AUTOSAR XML (schema 4-2-2)
package /STELLANTIS/EPT/ASWCs
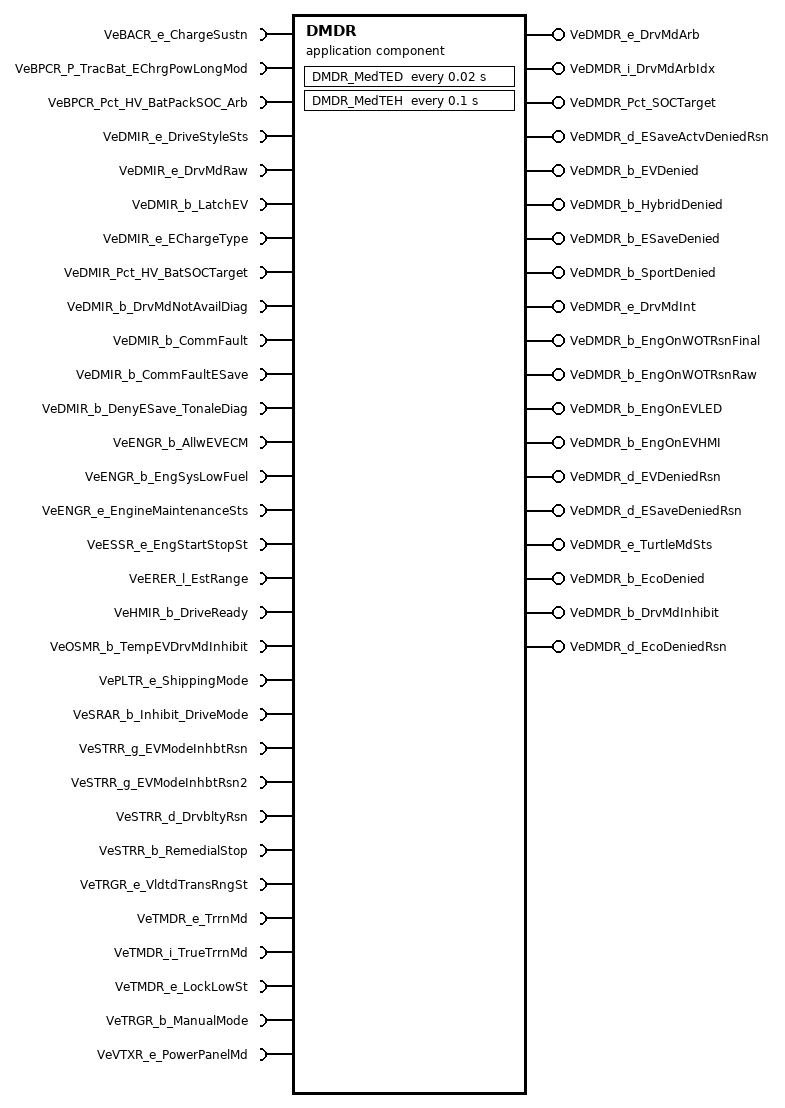
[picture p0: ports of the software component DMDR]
  application sw component type DMDR
    31 x require port:
      VeBACR_e_ChargeSustn: nonqueued-receiver-com-spec{data-element=Value, init-value=CeBACR_e_ChargeSustaining}, required-interface=VeBACR_e_ChargeSustn
      VeBPCR_P_TracBat_EChrgPowLongMod: nonqueued-receiver-com-spec{data-element=Value, init-value=0}, required-interface=VeBPCR_P_TracBat_EChrgPowLongMod
      VeBPCR_Pct_HV_BatPackSOC_Arb: nonqueued-receiver-com-spec{data-element=Value, init-value=0}, required-interface=VeBPCR_Pct_HV_BatPackSOC_Arb
      VeDMIR_e_DriveStyleSts: nonqueued-receiver-com-spec{data-element=Value, init-value=CeDMIR_e_Normal}, required-interface=VeDMIR_e_DriveStyleSts
      VeDMIR_e_DrvMdRaw: nonqueued-receiver-com-spec{data-element=Value, init-value=CeDMDR_e_NoDrvMd}, required-interface=VeDMIR_e_DrvMdRaw
      VeDMIR_b_LatchEV: nonqueued-receiver-com-spec{data-element=Value, init-value=0}, required-interface=VeDMIR_b_LatchEV
      VeDMIR_e_EChargeType: nonqueued-receiver-com-spec{data-element=Value, init-value=CeDMDR_e_Passive_Charging}, required-interface=VeDMIR_e_EChargeType
      VeDMIR_Pct_HV_BatSOCTarget: nonqueued-receiver-com-spec{data-element=Value, init-value=0}, required-interface=VeDMIR_Pct_HV_BatSOCTarget
      VeDMIR_b_DrvMdNotAvailDiag: nonqueued-receiver-com-spec{data-element=Value, init-value=0}, required-interface=VeDMIR_b_DrvMdNotAvailDiag
      VeDMIR_b_CommFault: nonqueued-receiver-com-spec{data-element=Value, init-value=0}, required-interface=VeDMIR_b_CommFault
      VeDMIR_b_CommFaultESave: nonqueued-receiver-com-spec{data-element=Value, init-value=0}, required-interface=VeDMIR_b_CommFaultESave
      VeDMIR_b_DenyESave_TonaleDiag: nonqueued-receiver-com-spec{data-element=Value, init-value=0}, required-interface=VeDMIR_b_DenyESave_TonaleDiag
      VeENGR_b_AllwEVECM: nonqueued-receiver-com-spec{data-element=Value, init-value=0}, required-interface=VeENGR_b_AllwEVECM
      VeENGR_b_EngSysLowFuel: nonqueued-receiver-com-spec{data-element=Value, init-value=0}, required-interface=VeENGR_b_EngSysLowFuel
      VeENGR_e_EngineMaintenanceSts: nonqueued-receiver-com-spec{data-element=Value, init-value=CeENGR_e_Inactive}, required-interface=VeENGR_e_EngineMaintenanceSts
      VeESSR_e_EngStartStopSt: nonqueued-receiver-com-spec{data-element=Value, init-value=CeESSR_e_EngOff}, required-interface=VeESSR_e_EngStartStopSt
      VeERER_l_EstRange: nonqueued-receiver-com-spec{data-element=Value, init-value=0}, required-interface=VeERER_l_EstRange
      VeHMIR_b_DriveReady: nonqueued-receiver-com-spec{data-element=Value, init-value=0}, required-interface=VeHMIR_b_DriveReady
      VeOSMR_b_TempEVDrvMdInhibit: nonqueued-receiver-com-spec{data-element=Value, init-value=0}, required-interface=VeOSMR_b_TempEVDrvMdInhibit
      VePLTR_e_ShippingMode: nonqueued-receiver-com-spec{data-element=Value, init-value=CePLTR_e_ShipingMode_CUST_MD}, required-interface=VePLTR_e_ShippingMode
      VeSRAR_b_Inhibit_DriveMode: nonqueued-receiver-com-spec{data-element=Value, init-value=0}, required-interface=VeSRAR_b_Inhibit_DriveMode
      VeSTRR_g_EVModeInhbtRsn: nonqueued-receiver-com-spec{data-element=Value, init-value=0}, required-interface=VeSTRR_g_EVModeInhbtRsn
      VeSTRR_g_EVModeInhbtRsn2: nonqueued-receiver-com-spec{data-element=Value, init-value=0}, required-interface=VeSTRR_g_EVModeInhbtRsn2
      VeSTRR_d_DrvbltyRsn: nonqueued-receiver-com-spec{data-element=Value, init-value=0}, required-interface=VeSTRR_d_DrvbltyRsn
      VeSTRR_b_RemedialStop: nonqueued-receiver-com-spec{data-element=Value, init-value=0}, required-interface=VeSTRR_b_RemedialStop
      VeTRGR_e_VldtdTransRngSt: nonqueued-receiver-com-spec{data-element=Value, init-value=CeTRGR_e_NoSelectionAvailable}, required-interface=VeTRGR_e_VldtdTransRngSt
      VeTMDR_e_TrrnMd: nonqueued-receiver-com-spec{data-element=Value, init-value=CeTMDR_e_NotDefine}, required-interface=VeTMDR_e_TrrnMd
      VeTMDR_i_TrueTrrnMd: nonqueued-receiver-com-spec{data-element=Value, init-value=0}, required-interface=VeTMDR_i_TrueTrrnMd
      VeTMDR_e_LockLowSt: nonqueued-receiver-com-spec{data-element=Value, init-value=CeTMDR_e_Off}, required-interface=VeTMDR_e_LockLowSt
      VeTRGR_b_ManualMode: nonqueued-receiver-com-spec{data-element=Value, init-value=0}, required-interface=VeTRGR_b_ManualMode
      VeVTXR_e_PowerPanelMd: nonqueued-receiver-com-spec{data-element=Value, init-value=CeVTXR_e_DefaultMd}, required-interface=VeVTXR_e_PowerPanelMd
    19 x provide port:
      VeDMDR_e_DrvMdArb: variation-point={short-label=vpVeDMDR_e_DrvMdArb, sw-syscond=1}, nonqueued-sender-com-spec{data-element=Value, init-value=CeDMDR_e_NoDrvMd}, provided-interface=VeDMDR_e_DrvMdArb
      VeDMDR_i_DrvMdArbIdx: variation-point={short-label=vpVeDMDR_i_DrvMdArbIdx, sw-syscond=1}, nonqueued-sender-com-spec{data-element=Value, init-value=0}, provided-interface=VeDMDR_i_DrvMdArbIdx
      VeDMDR_Pct_SOCTarget: variation-point={short-label=vpVeDMDR_Pct_SOCTarget, sw-syscond=1}, nonqueued-sender-com-spec{data-element=Value, init-value=0}, provided-interface=VeDMDR_Pct_SOCTarget
      VeDMDR_d_ESaveActvDeniedRsn: variation-point={short-label=vpVeDMDR_d_ESaveActvDeniedRsn, sw-syscond=1}, nonqueued-sender-com-spec{data-element=Value, init-value=0}, provided-interface=VeDMDR_d_ESaveActvDeniedRsn
      VeDMDR_b_EVDenied: variation-point={short-label=vpVeDMDR_b_EVDenied, sw-syscond=1}, nonqueued-sender-com-spec{data-element=Value, init-value=0}, provided-interface=VeDMDR_b_EVDenied
      VeDMDR_b_HybridDenied: variation-point={short-label=vpVeDMDR_b_HybridDenied, sw-syscond=1}, nonqueued-sender-com-spec{data-element=Value, init-value=0}, provided-interface=VeDMDR_b_HybridDenied
      VeDMDR_b_ESaveDenied: variation-point={short-label=vpVeDMDR_b_ESaveDenied, sw-syscond=1}, nonqueued-sender-com-spec{data-element=Value, init-value=0}, provided-interface=VeDMDR_b_ESaveDenied
      VeDMDR_b_SportDenied: variation-point={short-label=vpVeDMDR_b_SportDenied, sw-syscond=1}, nonqueued-sender-com-spec{data-element=Value, init-value=0}, provided-interface=VeDMDR_b_SportDenied
      VeDMDR_e_DrvMdInt: variation-point={short-label=vpVeDMDR_e_DrvMdInt, sw-syscond=1}, nonqueued-sender-com-spec{data-element=Value, init-value=CeDMDR_e_NoDrvMd}, provided-interface=VeDMDR_e_DrvMdInt
      VeDMDR_b_EngOnWOTRsnFinal: variation-point={short-label=vpVeDMDR_b_EngOnWOTRsnFinal, sw-syscond=1}, nonqueued-sender-com-spec{data-element=Value, init-value=0}, provided-interface=VeDMDR_b_EngOnWOTRsnFinal
      VeDMDR_b_EngOnWOTRsnRaw: variation-point={short-label=vpVeDMDR_b_EngOnWOTRsnRaw, sw-syscond=1}, nonqueued-sender-com-spec{data-element=Value, init-value=0}, provided-interface=VeDMDR_b_EngOnWOTRsnRaw
      VeDMDR_b_EngOnEVLED: variation-point={short-label=vpVeDMDR_b_EngOnEVLED, sw-syscond=1}, nonqueued-sender-com-spec{data-element=Value, init-value=0}, provided-interface=VeDMDR_b_EngOnEVLED
      VeDMDR_b_EngOnEVHMI: variation-point={short-label=vpVeDMDR_b_EngOnEVHMI, sw-syscond=1}, nonqueued-sender-com-spec{data-element=Value, init-value=0}, provided-interface=VeDMDR_b_EngOnEVHMI
      VeDMDR_d_EVDeniedRsn: variation-point={short-label=vpVeDMDR_d_EVDeniedRsn, sw-syscond=1}, nonqueued-sender-com-spec{data-element=Value, init-value=0}, provided-interface=VeDMDR_d_EVDeniedRsn
      VeDMDR_d_ESaveDeniedRsn: variation-point={short-label=vpVeDMDR_d_ESaveDeniedRsn, sw-syscond=1}, nonqueued-sender-com-spec{data-element=Value, init-value=0}, provided-interface=VeDMDR_d_ESaveDeniedRsn
      VeDMDR_e_TurtleMdSts: variation-point={short-label=vpVeDMDR_e_TurtleMdSts, sw-syscond=1}, nonqueued-sender-com-spec{data-element=Value, init-value=CeDMDR_e_No_Turtle_Mode}, provided-interface=VeDMDR_e_TurtleMdSts
      VeDMDR_b_EcoDenied: variation-point={short-label=vpVeDMDR_b_EcoDenied, sw-syscond=1}, nonqueued-sender-com-spec{data-element=Value, init-value=0}, provided-interface=VeDMDR_b_EcoDenied
      VeDMDR_b_DrvMdInhibit: nonqueued-sender-com-spec{data-element=Value, init-value=0}, provided-interface=VeDMDR_b_DrvMdInhibit
      VeDMDR_d_EcoDeniedRsn: variation-point={short-label=vpVeDMDR_d_EcoDeniedRsn, sw-syscond=1}, nonqueued-sender-com-spec{data-element=Value, init-value=0}, provided-interface=VeDMDR_d_EcoDeniedRsn
    behavior IB_DMDR: data-type-mapping=msADTtoIDTMapping, handle-termination-and-restart=NO-SUPPORT
      timing event Event_MedTED: start-on-event=DMDR_MedTED, period=0.02
      timing event Event_MedTEH: start-on-event=DMDR_MedTEH, period=0.1
      init event Event_DMDR_ac_Init: start-on-event=DMDR_ac_Init
      init event Event_PwrOn: start-on-event=DMDR_PwrOn
      explicit-inter-runnable-variables:
        5 x data, all with category=VALUE, sw-calibration-access=READ-ONLY:
          VeDMDC_e_DriveStyleSts_write_IRV: type=TeDMIR_e_DriveStyleSts, init-value=CeDMIR_e_Normal
          VeDMDC_e_TerrainMd_write_IRV: type=TeTMDR_e_TrrnMd, init-value=CeTMDR_e_NotDefine
          VeDMDC_i_TerrainMdIdx_write_IRV: type=UInt8, init-value=0
          VeDMDC_b_ShippingMd_write_IRV: type=TePLTR_e_ShipingMode, init-value=CePLTR_e_ShipingMode_CUST_MD
          VeDMDR_b_Inhibit_DriveMode_write_IRV: type=Boolean, init-value=0
      4 x runnable:
        DMDR_ac_Init
          data-send-points:
            access OUT_VeDMDR_e_DrvMdArb_Value: accessed-variable=VeDMDR_e_DrvMdArb.Value, variation-point={short-label=vpOUT_VeDMDR_e_DrvMdArb_Value, sw-syscond=1}
            access OUT_VeDMDR_e_DrvMdInt_Value: accessed-variable=VeDMDR_e_DrvMdInt.Value, variation-point={short-label=vpOUT_VeDMDR_e_DrvMdInt_Value, sw-syscond=1}
            access OUT_VeDMDR_e_TurtleMdSts_Value: accessed-variable=VeDMDR_e_TurtleMdSts.Value, variation-point={short-label=vpOUT_VeDMDR_e_TurtleMdSts_Value, sw-syscond=1}
        DMDR_PwrOn
          data-send-points:
            19 x access:
              OUT_VeDMDR_e_DrvMdArb_Value: accessed-variable=VeDMDR_e_DrvMdArb.Value, variation-point={short-label=vpOUT_VeDMDR_e_DrvMdArb_Value, sw-syscond=1}
              OUT_VeDMDR_i_DrvMdArbIdx_Value: accessed-variable=VeDMDR_i_DrvMdArbIdx.Value, variation-point={short-label=vpOUT_VeDMDR_i_DrvMdArbIdx_Value, sw-syscond=1}
              OUT_VeDMDR_Pct_SOCTarget_Value: accessed-variable=VeDMDR_Pct_SOCTarget.Value, variation-point={short-label=vpOUT_VeDMDR_Pct_SOCTarget_Value, sw-syscond=1}
              OUT_VeDMDR_e_DrvMdInt_Value: accessed-variable=VeDMDR_e_DrvMdInt.Value, variation-point={short-label=vpOUT_VeDMDR_e_DrvMdInt_Value, sw-syscond=1}
              OUT_VeDMDR_b_EngOnWOTRsnFinal_Value: accessed-variable=VeDMDR_b_EngOnWOTRsnFinal.Value, variation-point={short-label=vpOUT_VeDMDR_b_EngOnWOTRsnFinal_Value, sw-syscond=1}
              OUT_VeDMDR_b_EngOnWOTRsnRaw_Value: accessed-variable=VeDMDR_b_EngOnWOTRsnRaw.Value, variation-point={short-label=vpOUT_VeDMDR_b_EngOnWOTRsnRaw_Value, sw-syscond=1}
              OUT_VeDMDR_b_EngOnEVLED_Value: accessed-variable=VeDMDR_b_EngOnEVLED.Value, variation-point={short-label=vpOUT_VeDMDR_b_EngOnEVLED_Value, sw-syscond=1}
              OUT_VeDMDR_b_EngOnEVHMI_Value: accessed-variable=VeDMDR_b_EngOnEVHMI.Value, variation-point={short-label=vpOUT_VeDMDR_b_EngOnEVHMI_Value, sw-syscond=1}
              OUT_VeDMDR_d_EcoDeniedRsn_Value: accessed-variable=VeDMDR_d_EcoDeniedRsn.Value, variation-point={short-label=vpOUT_VeDMDR_d_EcoDeniedRsn_Value, sw-syscond=1}
              OUT_VeDMDR_d_ESaveActvDeniedRsn_Value: accessed-variable=VeDMDR_d_ESaveActvDeniedRsn.Value, variation-point={short-label=vpOUT_VeDMDR_d_ESaveActvDeniedRsn_Value, sw-syscond=1}
              OUT_VeDMDR_d_EVDeniedRsn_Value: accessed-variable=VeDMDR_d_EVDeniedRsn.Value, variation-point={short-label=vpOUT_VeDMDR_d_EVDeniedRsn_Value, sw-syscond=1}
              OUT_VeDMDR_d_ESaveDeniedRsn_Value: accessed-variable=VeDMDR_d_ESaveDeniedRsn.Value, variation-point={short-label=vpOUT_VeDMDR_d_ESaveDeniedRsn_Value, sw-syscond=1}
              OUT_VeDMDR_b_EcoDenied_Value: accessed-variable=VeDMDR_b_EcoDenied.Value, variation-point={short-label=vpOUT_VeDMDR_b_EcoDenied_Value, sw-syscond=1}
              OUT_VeDMDR_b_EVDenied_Value: accessed-variable=VeDMDR_b_EVDenied.Value, variation-point={short-label=vpOUT_VeDMDR_b_EVDenied_Value, sw-syscond=1}
              OUT_VeDMDR_b_HybridDenied_Value: accessed-variable=VeDMDR_b_HybridDenied.Value, variation-point={short-label=vpOUT_VeDMDR_b_HybridDenied_Value, sw-syscond=1}
              OUT_VeDMDR_b_ESaveDenied_Value: accessed-variable=VeDMDR_b_ESaveDenied.Value, variation-point={short-label=vpOUT_VeDMDR_b_ESaveDenied_Value, sw-syscond=1}
              OUT_VeDMDR_b_SportDenied_Value: accessed-variable=VeDMDR_b_SportDenied.Value, variation-point={short-label=vpOUT_VeDMDR_b_SportDenied_Value, sw-syscond=1}
              OUT_VeDMDR_e_TurtleMdSts_Value: accessed-variable=VeDMDR_e_TurtleMdSts.Value, variation-point={short-label=vpOUT_VeDMDR_e_TurtleMdSts_Value, sw-syscond=1}
              OUT_VeDMDR_b_DrvMdInhibit_Value: accessed-variable=VeDMDR_b_DrvMdInhibit.Value
          written-local-variables:
            5 x access:
              WV_VeDMDR_b_Inhibit_DriveMode_write_IRV: accessed-variable=VeDMDR_b_Inhibit_DriveMode_write_IRV
              WV_VeDMDC_e_DriveStyleSts_write_IRV: accessed-variable=VeDMDC_e_DriveStyleSts_write_IRV
              WV_VeDMDC_b_ShippingMd_write_IRV: accessed-variable=VeDMDC_b_ShippingMd_write_IRV
              WV_VeDMDC_e_TerrainMd_write_IRV: accessed-variable=VeDMDC_e_TerrainMd_write_IRV
              WV_VeDMDC_i_TerrainMdIdx_write_IRV: accessed-variable=VeDMDC_i_TerrainMdIdx_write_IRV
        DMDR_MedTED
          data-receive-point-by-arguments:
            31 x access:
              IN_VeBACR_e_ChargeSustn_Value: accessed-variable=VeBACR_e_ChargeSustn.Value
              IN_VeBPCR_P_TracBat_EChrgPowLongMod_Value: accessed-variable=VeBPCR_P_TracBat_EChrgPowLongMod.Value
              IN_VeBPCR_Pct_HV_BatPackSOC_Arb_Value: accessed-variable=VeBPCR_Pct_HV_BatPackSOC_Arb.Value
              IN_VeDMIR_Pct_HV_BatSOCTarget_Value: accessed-variable=VeDMIR_Pct_HV_BatSOCTarget.Value
              IN_VeDMIR_b_CommFault_Value: accessed-variable=VeDMIR_b_CommFault.Value
              IN_VeDMIR_b_CommFaultESave_Value: accessed-variable=VeDMIR_b_CommFaultESave.Value
              IN_VeDMIR_b_DenyESave_TonaleDiag_Value: accessed-variable=VeDMIR_b_DenyESave_TonaleDiag.Value
              IN_VeDMIR_b_DrvMdNotAvailDiag_Value: accessed-variable=VeDMIR_b_DrvMdNotAvailDiag.Value
              IN_VeDMIR_b_LatchEV_Value: accessed-variable=VeDMIR_b_LatchEV.Value
              IN_VeDMIR_e_DriveStyleSts_Value: accessed-variable=VeDMIR_e_DriveStyleSts.Value
              IN_VeDMIR_e_DrvMdRaw_Value: accessed-variable=VeDMIR_e_DrvMdRaw.Value
              IN_VeDMIR_e_EChargeType_Value: accessed-variable=VeDMIR_e_EChargeType.Value
              IN_VeENGR_b_AllwEVECM_Value: accessed-variable=VeENGR_b_AllwEVECM.Value
              IN_VeENGR_b_EngSysLowFuel_Value: accessed-variable=VeENGR_b_EngSysLowFuel.Value
              IN_VeENGR_e_EngineMaintenanceSts_Value: accessed-variable=VeENGR_e_EngineMaintenanceSts.Value
              IN_VeERER_l_EstRange_Value: accessed-variable=VeERER_l_EstRange.Value
              IN_VeESSR_e_EngStartStopSt_Value: accessed-variable=VeESSR_e_EngStartStopSt.Value
              IN_VeHMIR_b_DriveReady_Value: accessed-variable=VeHMIR_b_DriveReady.Value
              IN_VeOSMR_b_TempEVDrvMdInhibit_Value: accessed-variable=VeOSMR_b_TempEVDrvMdInhibit.Value
              IN_VePLTR_e_ShippingMode_Value: accessed-variable=VePLTR_e_ShippingMode.Value
              IN_VeSRAR_b_Inhibit_DriveMode_Value: accessed-variable=VeSRAR_b_Inhibit_DriveMode.Value
              IN_VeSTRR_b_RemedialStop_Value: accessed-variable=VeSTRR_b_RemedialStop.Value
              IN_VeSTRR_d_DrvbltyRsn_Value: accessed-variable=VeSTRR_d_DrvbltyRsn.Value
              IN_VeSTRR_g_EVModeInhbtRsn_Value: accessed-variable=VeSTRR_g_EVModeInhbtRsn.Value
              IN_VeSTRR_g_EVModeInhbtRsn2_Value: accessed-variable=VeSTRR_g_EVModeInhbtRsn2.Value
              IN_VeTMDR_e_LockLowSt_Value: accessed-variable=VeTMDR_e_LockLowSt.Value
              IN_VeTMDR_e_TrrnMd_Value: accessed-variable=VeTMDR_e_TrrnMd.Value
              IN_VeTMDR_i_TrueTrrnMd_Value: accessed-variable=VeTMDR_i_TrueTrrnMd.Value
              IN_VeTRGR_b_ManualMode_Value: accessed-variable=VeTRGR_b_ManualMode.Value
              IN_VeTRGR_e_VldtdTransRngSt_Value: accessed-variable=VeTRGR_e_VldtdTransRngSt.Value
              IN_VeVTXR_e_PowerPanelMd_Value: accessed-variable=VeVTXR_e_PowerPanelMd.Value
          data-send-points:
            19 x access:
              OUT_VeDMDR_b_DrvMdInhibit_Value: accessed-variable=VeDMDR_b_DrvMdInhibit.Value
              OUT_VeDMDR_e_DrvMdArb_Value: accessed-variable=VeDMDR_e_DrvMdArb.Value, variation-point={short-label=vpOUT_VeDMDR_e_DrvMdArb_Value, sw-syscond=1}
              OUT_VeDMDR_i_DrvMdArbIdx_Value: accessed-variable=VeDMDR_i_DrvMdArbIdx.Value, variation-point={short-label=vpOUT_VeDMDR_i_DrvMdArbIdx_Value, sw-syscond=1}
              OUT_VeDMDR_Pct_SOCTarget_Value: accessed-variable=VeDMDR_Pct_SOCTarget.Value, variation-point={short-label=vpOUT_VeDMDR_Pct_SOCTarget_Value, sw-syscond=1}
              OUT_VeDMDR_e_DrvMdInt_Value: accessed-variable=VeDMDR_e_DrvMdInt.Value, variation-point={short-label=vpOUT_VeDMDR_e_DrvMdInt_Value, sw-syscond=1}
              OUT_VeDMDR_b_EngOnWOTRsnFinal_Value: accessed-variable=VeDMDR_b_EngOnWOTRsnFinal.Value, variation-point={short-label=vpOUT_VeDMDR_b_EngOnWOTRsnFinal_Value, sw-syscond=1}
              OUT_VeDMDR_b_EngOnWOTRsnRaw_Value: accessed-variable=VeDMDR_b_EngOnWOTRsnRaw.Value, variation-point={short-label=vpOUT_VeDMDR_b_EngOnWOTRsnRaw_Value, sw-syscond=1}
              OUT_VeDMDR_b_EngOnEVLED_Value: accessed-variable=VeDMDR_b_EngOnEVLED.Value, variation-point={short-label=vpOUT_VeDMDR_b_EngOnEVLED_Value, sw-syscond=1}
              OUT_VeDMDR_b_EngOnEVHMI_Value: accessed-variable=VeDMDR_b_EngOnEVHMI.Value, variation-point={short-label=vpOUT_VeDMDR_b_EngOnEVHMI_Value, sw-syscond=1}
              OUT_VeDMDR_d_ESaveActvDeniedRsn_Value: accessed-variable=VeDMDR_d_ESaveActvDeniedRsn.Value, variation-point={short-label=vpOUT_VeDMDR_d_ESaveActvDeniedRsn_Value, sw-syscond=1}
              OUT_VeDMDR_d_EVDeniedRsn_Value: accessed-variable=VeDMDR_d_EVDeniedRsn.Value, variation-point={short-label=vpOUT_VeDMDR_d_EVDeniedRsn_Value, sw-syscond=1}
              OUT_VeDMDR_d_ESaveDeniedRsn_Value: accessed-variable=VeDMDR_d_ESaveDeniedRsn.Value, variation-point={short-label=vpOUT_VeDMDR_d_ESaveDeniedRsn_Value, sw-syscond=1}
              OUT_VeDMDR_d_EcoDeniedRsn_Value: accessed-variable=VeDMDR_d_EcoDeniedRsn.Value, variation-point={short-label=vpOUT_VeDMDR_d_EcoDeniedRsn_Value, sw-syscond=1}
              OUT_VeDMDR_b_EcoDenied_Value: accessed-variable=VeDMDR_b_EcoDenied.Value, variation-point={short-label=vpOUT_VeDMDR_b_EcoDenied_Value, sw-syscond=1}
              OUT_VeDMDR_b_EVDenied_Value: accessed-variable=VeDMDR_b_EVDenied.Value, variation-point={short-label=vpOUT_VeDMDR_b_EVDenied_Value, sw-syscond=1}
              OUT_VeDMDR_b_HybridDenied_Value: accessed-variable=VeDMDR_b_HybridDenied.Value, variation-point={short-label=vpOUT_VeDMDR_b_HybridDenied_Value, sw-syscond=1}
              OUT_VeDMDR_b_ESaveDenied_Value: accessed-variable=VeDMDR_b_ESaveDenied.Value, variation-point={short-label=vpOUT_VeDMDR_b_ESaveDenied_Value, sw-syscond=1}
              OUT_VeDMDR_b_SportDenied_Value: accessed-variable=VeDMDR_b_SportDenied.Value, variation-point={short-label=vpOUT_VeDMDR_b_SportDenied_Value, sw-syscond=1}
              OUT_VeDMDR_e_TurtleMdSts_Value: accessed-variable=VeDMDR_e_TurtleMdSts.Value, variation-point={short-label=vpOUT_VeDMDR_e_TurtleMdSts_Value, sw-syscond=1}
          written-local-variables:
            5 x access:
              WV_VeDMDC_b_ShippingMd_write_IRV: accessed-variable=VeDMDC_b_ShippingMd_write_IRV
              WV_VeDMDC_e_DriveStyleSts_write_IRV: accessed-variable=VeDMDC_e_DriveStyleSts_write_IRV
              WV_VeDMDC_e_TerrainMd_write_IRV: accessed-variable=VeDMDC_e_TerrainMd_write_IRV
              WV_VeDMDC_i_TerrainMdIdx_write_IRV: accessed-variable=VeDMDC_i_TerrainMdIdx_write_IRV
              WV_VeDMDR_b_Inhibit_DriveMode_write_IRV: accessed-variable=VeDMDR_b_Inhibit_DriveMode_write_IRV
        DMDR_MedTEH: variation-point={short-label=vpDMDR_MedTEH, sw-syscond=1}
          data-send-points:
            4 x access:
              OUT_VeDMDR_e_DrvMdArb_Value: accessed-variable=VeDMDR_e_DrvMdArb.Value, variation-point={short-label=vpOUT_VeDMDR_e_DrvMdArb_Value, sw-syscond=1}
              OUT_VeDMDR_i_DrvMdArbIdx_Value: accessed-variable=VeDMDR_i_DrvMdArbIdx.Value, variation-point={short-label=vpOUT_VeDMDR_i_DrvMdArbIdx_Value, sw-syscond=1}
              OUT_VeDMDR_b_EcoDenied_Value: accessed-variable=VeDMDR_b_EcoDenied.Value, variation-point={short-label=vpOUT_VeDMDR_b_EcoDenied_Value, sw-syscond=1}
              OUT_VeDMDR_d_EcoDeniedRsn_Value: accessed-variable=VeDMDR_d_EcoDeniedRsn.Value, variation-point={short-label=vpOUT_VeDMDR_d_EcoDeniedRsn_Value, sw-syscond=1}
          read-local-variables:
            5 x access:
              RV_VeDMDC_b_ShippingMd_write_IRV: accessed-variable=VeDMDC_b_ShippingMd_write_IRV, variation-point={short-label=vpRV_VeDMDC_b_ShippingMd_write_IRV, sw-syscond=1}
              RV_VeDMDC_e_DriveStyleSts_write_IRV: accessed-variable=VeDMDC_e_DriveStyleSts_write_IRV, variation-point={short-label=vpRV_VeDMDC_e_DriveStyleSts_write_IRV, sw-syscond=1}
              RV_VeDMDC_e_TerrainMd_write_IRV: accessed-variable=VeDMDC_e_TerrainMd_write_IRV, variation-point={short-label=vpRV_VeDMDC_e_TerrainMd_write_IRV, sw-syscond=1}
              RV_VeDMDC_i_TerrainMdIdx_write_IRV: accessed-variable=VeDMDC_i_TerrainMdIdx_write_IRV, variation-point={short-label=vpRV_VeDMDC_i_TerrainMdIdx_write_IRV, sw-syscond=1}
              RV_VeDMDR_b_Inhibit_DriveMode_write_IRV: accessed-variable=VeDMDR_b_Inhibit_DriveMode_write_IRV, variation-point={short-label=vpRV_VeDMDR_b_Inhibit_DriveMode_write_IRV, sw-syscond=1}
      7 x variation point proxy, all with category=CONDITION:
        Variant_DMDR_BEVEnbld: condition-access=1
        Variant_DMDR_FuncDsbld: condition-access=1
        Variant_DMDR_FuncEnbld: condition-access=0
        Variant_DMDR_FuncOrBEVEnbld: condition-access=1
        Variant_DMDR_SportMdNotOnTrrnMd: condition-access=0
        Variant_DMDR_TurtleMdDsbld: condition-access=0
        Variant_DMDR_TurtleMdEnbld: condition-access=1
